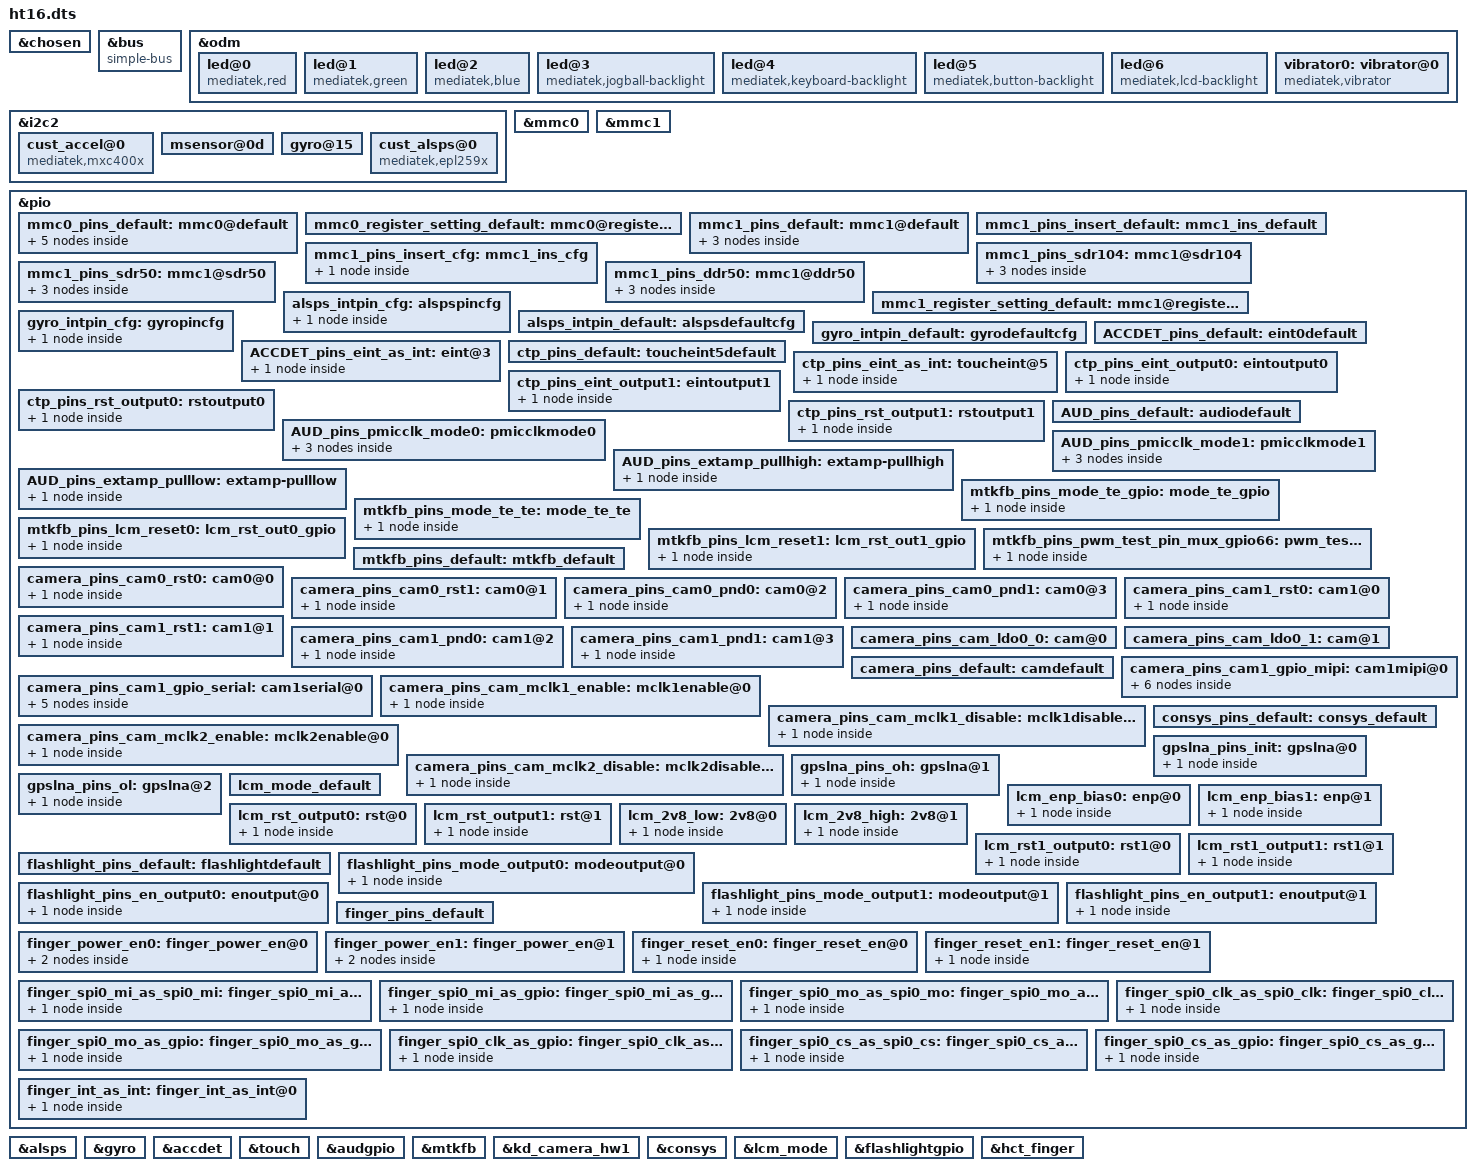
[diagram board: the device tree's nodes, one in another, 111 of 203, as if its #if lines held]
#include <generated/autoconf.h>
/dts-v1/;

#ifdef CONFIG_MTK_DTBO_FEATURE
/plugin/;
#include <dt-bindings/interrupt-controller/arm-gic.h>
#include <dt-bindings/interrupt-controller/irq.h>
#include "mt6580-pinfunc.h"
#include <dt-bindings/mmc/mt6580-msdc.h>
#else
#include "mt6580.dts"
#endif

/* chosen */
&chosen {
	bootargs = "console=tty0 console=ttyMT0,921600n1 root=/dev/ram initrd=0x84000000,0x400000 loglevel=8";
	/* fpga may has no lk, we need to specify display info here */
	/* fb buffer is reserved using this dts by memory node above */
	atag,videolfb-fb_base = <0x9E800000>;
	atag,videolfb-islcmfound = <1>;
	atag,videolfb-fps= <6000>;
	atag,videolfb-vramSize= <0x01800000>;
	atag,videolfb-lcmname= "nt35590_AUO";
};

&bus {
	compatible = "simple-bus";
	#address-cells = <1>;
	#size-cells = <1>;
	ranges = <0 0 0 0xffffffff>;
};

&odm {
	led@0 {
		compatible = "mediatek,red";
		led_mode = <0>;
		data = <1>;
		pwm_config = <0 0 0 0 0>;
	};
	led@1 {
		compatible = "mediatek,green";
		led_mode = <0>;
		data = <1>;
		pwm_config = <0 0 0 0 0>;
	};
	led@2 {
		compatible = "mediatek,blue";
		led_mode = <0>;
		data = <1>;
		pwm_config = <0 0 0 0 0>;
	};
	led@3 {
		compatible = "mediatek,jogball-backlight";
		led_mode = <0>;
		data = <1>;
		pwm_config = <0 0 0 0 0>;
	};
	led@4 {
		compatible = "mediatek,keyboard-backlight";
		led_mode = <0>;
		data = <1>;
		pwm_config = <0 0 0 0 0>;
	};
	led@5 {
		compatible = "mediatek,button-backlight";
		led_mode = <0>;
		data = <1>;
		pwm_config = <0 0 0 0 0>;
	};
	led@6 {
		compatible = "mediatek,lcd-backlight";
		led_mode = <5>;
		data = <1>;
		pwm_config = <0 0 0 0 0>;
	};
	vibrator0:vibrator@0 {
		compatible = "mediatek,vibrator";
		vib_timer = <25>;
		vib_limit = <9>;
		vib_vol= <6>;
	};
};

&i2c2 {
/* start sensor */
    cust_accel@0 {
		compatible				= "mediatek,mxc400x";
		i2c_num				    =  <2>;
		i2c_addr				= <0x15 0 0 0>;
		direction				= <3>;
		power_id				= <0xffff>;
		power_vol				= <0>;
		firlen					= <0>;
		is_batch_supported			= <0>;
    };

	msensor@0d {
		i2c_num = <2>;
		i2c_addr = <0x0D 0 0 0>;
		direction = <4>;
		power_id = <0xffff>;
		power_vol = <0>;
		is_batch_supported = <0>;
	};



	gyro@15 {
		i2c_num = <2>;
		i2c_addr = <0x15 0 0 0>;
		direction = <3>;
		power_id = <0xffff>;
		power_vol = <0>;
		firlen = <0>;
		is_batch_supported = <0>;
	};
    cust_alsps@0 {
        compatible            = "mediatek,epl259x";
        i2c_num	              = <2>;
        i2c_addr              = <0x49>;
        polling_mode_ps       = <0>;
        polling_mode_als      = <1>;
        power_id              = <0xffff>;
        power_vol             = <0>;
		als_level             = <0 400 900 1500 2325 3421 5067 6621 7062 8430 13274 27116 37694 57694 65535>;
		als_value             = <0 133 304 502 1004 2005 3058 4005 5008 6010 8000 12000 18000 20000 20000 20000>;
        ps_threshold_high	  = <200>;
        ps_threshold_low	  = <100>;
        is_batch_supported_ps = <0>;
        is_batch_supported_als= <0>;
    };
};

/* mmc start */
&mmc0 {
	clk_src = /bits/ 8 <MSDC0_CLKSRC_208MHZ>;
	bus-width = <8>;
	max-frequency = <208000000>;
	cap-mmc-highspeed;
	msdc-sys-suspend;
	mmc-hs200-1_8v;
	non-removable;
	pinctl = <&mmc0_pins_default>;
	register_setting = <&mmc0_register_setting_default>;
	host_function = /bits/ 8 <MSDC_EMMC>;
	bootable;
	status = "okay";
};

&mmc1 {
	clk_src = /bits/ 8 <MSDC1_CLKSRC_187MHZ>;
	bus-width = <4>;
	max-frequency = <208000000>;
	msdc-sys-suspend;
	cap-sd-highspeed;
	sd-uhs-sdr12;
	sd-uhs-sdr25;
	sd-uhs-sdr50;
	sd-uhs-sdr104;
	non-removable;
	pinctrl-names = "default","insert_cfg";
	pinctrl-0 = <&mmc1_pins_insert_default>;
	pinctrl-1 = <&mmc1_pins_insert_cfg>;
	pinctl = <&mmc1_pins_default>;
	pinctl_sdr104 = <&mmc1_pins_sdr104>;
	pinctl_sdr50 = <&mmc1_pins_sdr50>;
	pinctl_ddr50 = <&mmc1_pins_ddr50>;
	register_setting = <&mmc1_register_setting_default>;
	host_function = /bits/ 8 <MSDC_SD>;
	cd_level = /bits/ 8 <MSDC_CD_LOW>;
	cd-gpios = <&pio 3 0>;
	status = "okay";
};

&pio {
	mmc0_pins_default: mmc0@default {
		pins_cmd {
			drive-strength = /bits/ 8 <2>;
		};
		pins_dat {
			drive-strength = /bits/ 8 <2>;
		};
		pins_clk {
			drive-strength = /bits/ 8 <2>;
		};
		pins_rst {
			drive-strength = /bits/ 8 <2>;
		};
		pins_ds {
			drive-strength = /bits/ 8 <2>;
		};
	};

	mmc0_register_setting_default: mmc0@register_default {
		dat0rddly      = /bits/ 8 <0>;
		dat1rddly      = /bits/ 8 <0>;
		dat2rddly      = /bits/ 8 <0>;
		dat3rddly      = /bits/ 8 <0>;
		dat4rddly      = /bits/ 8 <0>;
		dat5rddly      = /bits/ 8 <0>;
		dat6rddly      = /bits/ 8 <0>;
		dat7rddly      = /bits/ 8 <0>;
		datwrddly      = /bits/ 8 <0>;
		cmdrrddly      = /bits/ 8 <0>;
		cmdrddly       = /bits/ 8 <0>;
		cmd_edge = /bits/ 8 <MSDC_SMPL_FALLING>;
		rdata_edge = /bits/ 8 <MSDC_SMPL_FALLING>;
		wdata_edge = /bits/ 8 <MSDC_SMPL_FALLING>;

		ett-hs200-cells = <12>;
		ett-hs200-default = <OFFSET_MSDC_PATCH_BIT0	MSDC_PB0_INT_DAT_LATCH_CK_SEL 0x0
			OFFSET_MSDC_PATCH_BIT0  MSDC_PB0_CKGEN_MSDC_DLY_SEL   0x0
			OFFSET_MSDC_PATCH_BIT1  MSDC_PB1_CMD_RSP_TA_CNTR      0x1
			OFFSET_MSDC_IOCON       MSDC_IOCON_RSPL               0x1
			OFFSET_MSDC_PAD_TUNE0   MSDC_PAD_TUNE0_CMDRDLY        0x0
			OFFSET_MSDC_PAD_TUNE0   MSDC_PAD_TUNE0_CMDRRDLY       0x0
			OFFSET_MSDC_PATCH_BIT1  MSDC_PB1_WRDAT_CRCS_TA_CNTR   0x1
			OFFSET_MSDC_PAD_TUNE0   MSDC_PAD_TUNE0_DATWRDLY       0x0
			OFFSET_MSDC_IOCON       MSDC_IOCON_W_D_SMPL           0x1
			OFFSET_MSDC_DAT_RDDLY0  MSDC_DAT_RDDLY0_D0            0x0
			OFFSET_MSDC_PAD_TUNE0   MSDC_PAD_TUNE0_DATRRDLY       0x0
			OFFSET_MSDC_PATCH_BIT0  MSDC_PB0_RD_DAT_SEL           0x1>;
	};

	mmc1_pins_default: mmc1@default {
		pins_cmd {
			drive-strength = /bits/ 8 <3>;
		};
		pins_dat {
			drive-strength = /bits/ 8 <3>;
		};
		pins_clk {
			drive-strength = /bits/ 8 <3>;
		};
	};

    mmc1_pins_insert_default: mmc1_ins_default {
	};
	mmc1_pins_insert_cfg: mmc1_ins_cfg {
		pins_insert {
			pins = <PINMUX_GPIO10__FUNC_EINT10>;
			input-schmitt-enable =<1>;
			slew-rate = <0>;
			bias-pull-up =<00>;
		};
	};
	
	mmc1_pins_sdr104: mmc1@sdr104 {
		pins_cmd {
			drive-strength = /bits/ 8 <2>;
		};
		pins_dat {
			drive-strength = /bits/ 8 <2>;
		};
		pins_clk {
			drive-strength = /bits/ 8 <3>;
		};
	};

	mmc1_pins_sdr50: mmc1@sdr50 {
		pins_cmd {
			drive-strength = /bits/ 8 <2>;
		};
		pins_dat {
			drive-strength = /bits/ 8 <2>;
		};
		pins_clk {
			drive-strength = /bits/ 8 <3>;
		};
	};

	mmc1_pins_ddr50: mmc1@ddr50 {
		pins_cmd {
			drive-strength = /bits/ 8 <2>;
		};
		pins_dat {
			drive-strength = /bits/ 8 <2>;
		};
		pins_clk {
			drive-strength = /bits/ 8 <3>;
		};
	};

	mmc1_register_setting_default: mmc1@register_default {
		dat0rddly      = /bits/ 8 <0>;
		dat1rddly      = /bits/ 8 <0>;
		dat2rddly      = /bits/ 8 <0>;
		dat3rddly      = /bits/ 8 <0>;
		datwrddly      = /bits/ 8 <0>;
		cmdrrddly      = /bits/ 8 <0>;
		cmdrddly       = /bits/ 8 <0>;
		cmd_edge = /bits/ 8 <MSDC_SMPL_FALLING>;
		rdata_edge = /bits/ 8 <MSDC_SMPL_FALLING>;
		wdata_edge = /bits/ 8 <MSDC_SMPL_FALLING>;
	};
};
/* mmc end */

&pio {
	alsps_intpin_cfg: alspspincfg {
	    pins_cmd_dat {
			pins = <PINMUX_GPIO6__FUNC_EINT6>;
			slew-rate = <0>;
			bias-pull-up = <00>;
		};
	};
	alsps_intpin_default: alspsdefaultcfg {
	};
	gyro_intpin_cfg: gyropincfg {
	    pins_cmd_dat {
			pins = <PINMUX_GPIO1__FUNC_GPIO1>;
			slew-rate = <0>;
			bias-pull-down = <00>;
		};
	};
	gyro_intpin_default: gyrodefaultcfg {
	};
};
&alsps {
	pinctrl-names = "pin_default", "pin_cfg";
	pinctrl-0 = <&alsps_intpin_default>;
	pinctrl-1 = <&alsps_intpin_cfg>;
	status = "okay";
};
&gyro {
	pinctrl-names = "pin_default", "pin_cfg";
	pinctrl-0 = <&gyro_intpin_default>;
	pinctrl-1 = <&gyro_intpin_cfg>;
	status = "okay";
};

&accdet {
	accdet-mic-vol = <7>;
	headset-mode-setting = <0x500 0x200 1 0x1F0 0x800 0x800 0x20>;
	accdet-plugout-debounce = <20>;
	/*1:ACC mode, 2:low cost without in bias, 6:low cost with in bias*/
	accdet-mic-mode = <1>;
	/*0--MD_MAX--UP_MAX--DW_MAX*/
	headset-three-key-threshold = <0 90 240 500>;
	/*0--MD_MAX--VOICE_MAX--UP_MAX--DW_MAX*/
	headset-four-key-threshold = <0 60 126 201 450>;
	/* ACCDET GPIO standardization ACC mode use */
	pinctrl-names = "default", "state_eint_as_int";
	pinctrl-0 = <&ACCDET_pins_default>;
	pinctrl-1 = <&ACCDET_pins_eint_as_int>;
	status = "okay";
};
&pio {
	ACCDET_pins_default: eint0default {
	};
	ACCDET_pins_eint_as_int: eint@3 {
		pins_cmd_dat {
			pins = <PINMUX_GPIO19__FUNC_EINT3>;
			slew-rate = <0>;
			bias-disable;
		};
	};
};
/*ACCDET END*/
/* TOUCH GPIO standardization */
&touch {
	tpd-resolution = <720 1280>;
	use-tpd-button = <1>;
	tpd-key-num = <4>;
	tpd-key-local= <139 158 172 0>;
	tpd-key-dim-local = <430 1350 60 50  90 1350 60 50 270 1350 60 50 630 1350 60 50>;
	tpd-max-touch-num = <5>;
	tpd-filter-enable = <1>;
	tpd-filter-pixel-density = <93>;
	tpd-filter-custom-prameters = <0 0 0 0 0 0 0 0 0 0 0 0>;
	tpd-filter-custom-speed = <0 0 0>;
	pinctrl-names = "default", "state_eint_as_int", "state_eint_output0", "state_eint_output1",
		"state_rst_output0", "state_rst_output1";
	pinctrl-0 = <&ctp_pins_default>;
	pinctrl-1 = <&ctp_pins_eint_as_int>;
	pinctrl-2 = <&ctp_pins_eint_output0>;
	pinctrl-3 = <&ctp_pins_eint_output1>;
	pinctrl-4 = <&ctp_pins_rst_output0>;
	pinctrl-5 = <&ctp_pins_rst_output1>;
	status = "okay";
};
&pio {
	ctp_pins_default: toucheint5default {
    };
	ctp_pins_eint_as_int: toucheint@5 {
		pins_cmd_dat {
			pins = <PINMUX_GPIO5__FUNC_EINT5>;
			slew-rate = <0>;
			bias-disable;
		};
	};
	ctp_pins_eint_output0: eintoutput0 {
		pins_cmd_dat {
			pins = <PINMUX_GPIO5__FUNC_GPIO5>;
			slew-rate = <1>;
			output-low;
		};
	};
	ctp_pins_eint_output1: eintoutput1 {
		pins_cmd_dat {
			pins = <PINMUX_GPIO5__FUNC_GPIO5>;
			slew-rate = <1>;
			output-high;
		};
	};
	ctp_pins_rst_output0: rstoutput0 {
		pins_cmd_dat {
			pins = <PINMUX_GPIO18__FUNC_GPIO18>;
			slew-rate = <1>;
			output-low;
		};
	};
	ctp_pins_rst_output1: rstoutput1 {
		pins_cmd_dat {
			pins = <PINMUX_GPIO18__FUNC_GPIO18>;
			slew-rate = <1>;
			output-high;
		};
	};
};
/* TOUCH end */

/* AUDIO GPIO standardization */
&audgpio {
	pinctrl-names = "default", "audpmicclk-mode0", "audpmicclk-mode1", "extamp-pullhigh", "extamp-pulllow";
	pinctrl-0 = <&AUD_pins_default>;
	pinctrl-1 = <&AUD_pins_pmicclk_mode0>;
	pinctrl-2 = <&AUD_pins_pmicclk_mode1>;
	pinctrl-3 = <&AUD_pins_extamp_pullhigh>;
	pinctrl-4 = <&AUD_pins_extamp_pulllow>;
	status = "okay";
};
&pio {
	AUD_pins_default: audiodefault {
	};
	AUD_pins_pmicclk_mode0: pmicclkmode0 {
		pins_cmd0_dat {
			pins = <PINMUX_GPIO26__FUNC_GPIO26>;
		};
		pins_cmd1_dat {
			pins = <PINMUX_GPIO28__FUNC_GPIO28>;
		};
		pins_cmd2_dat {
			pins = <PINMUX_GPIO27__FUNC_GPIO27>;
		};
	};
	AUD_pins_pmicclk_mode1: pmicclkmode1 {
		pins_cmd0_dat {
			pins = <PINMUX_GPIO26__FUNC_AUD_CLK_MOSI>;
		};
		pins_cmd1_dat {
			pins = <PINMUX_GPIO28__FUNC_AUD_DAT_MISO>;
		};
		pins_cmd2_dat {
			pins = <PINMUX_GPIO27__FUNC_AUD_DAT_MOSI>;
		};
	};
    AUD_pins_extamp_pullhigh: extamp-pullhigh{
        pins_cmd_dat{
			pins = <PINMUX_GPIO20__FUNC_GPIO20>;
			slew-rate = <1>;
			output-high;
        };
	};
	AUD_pins_extamp_pulllow: extamp-pulllow{
        pins_cmd_dat{
			pins = <PINMUX_GPIO20__FUNC_GPIO20>;
			slew-rate = <1>;
			output-low;
        };
	};
};
/* AUDIO end */

/* DISPSYS GPIO standardization */
&pio {

	mtkfb_pins_mode_te_gpio: mode_te_gpio {
		pins_cmd_dat {
			pins = <PINMUX_GPIO68__FUNC_GPIO68>;
		};
	};

	mtkfb_pins_mode_te_te: mode_te_te {
		pins_cmd_dat {
			pins = <PINMUX_GPIO68__FUNC_DSI_TE>;
		};
	};

	mtkfb_pins_lcm_reset0: lcm_rst_out0_gpio {
		pins_cmd_dat {
			pins = <PINMUX_GPIO70__FUNC_LCM_RST>;
			slew-rate = <1>;
			output-low;
		};
	};

	mtkfb_pins_lcm_reset1: lcm_rst_out1_gpio {
		pins_cmd_dat {
			pins = <PINMUX_GPIO70__FUNC_LCM_RST>;
			slew-rate = <1>;
			output-high;
		};
	};

	mtkfb_pins_pwm_test_pin_mux_gpio66: pwm_test_pin_mux_gpio66 {
		pins_cmd_dat {
			pins = <PINMUX_GPIO66__FUNC_DISP_PWM>;
			slew-rate = <1>;
		};
	};

	mtkfb_pins_default: mtkfb_default {
	};
};

&mtkfb {
	pinctrl-names = "default", "mode_te_gpio", "mode_te_te",
			"lcm_rst_out0_gpio", "lcm_rst_out1_gpio",
			"pwm_test_pin_mux_gpio66";
	pinctrl-0 = <&mtkfb_pins_default>;
	pinctrl-1 = <&mtkfb_pins_mode_te_gpio>;
	pinctrl-2 = <&mtkfb_pins_mode_te_te>;
	pinctrl-3 = <&mtkfb_pins_lcm_reset0>;
	pinctrl-4 = <&mtkfb_pins_lcm_reset1>;
	pinctrl-5 = <&mtkfb_pins_pwm_test_pin_mux_gpio66>;
	status = "okay";
};
/* DISPSYS GPIO standardization end */
/* CAMERA GPIO standardization */
&pio {
	camera_pins_cam0_rst0: cam0@0 {
	    pins_cmd_dat {
			pins = <PINMUX_GPIO73__FUNC_GPIO73>;/*GPIO_CAMERA_CMRST_PIN*/
			slew-rate = <1>; /*direction 0:in, 1:out*/
			output-low;/*direction out used only. output_low or high*/
		};
	};
	camera_pins_cam0_rst1: cam0@1 {
	    pins_cmd_dat {
			pins = <PINMUX_GPIO73__FUNC_GPIO73>;/*GPIO_CAMERA_CMRST_PIN*/
			slew-rate = <1>;
			output-high;
		};
	};
	camera_pins_cam0_pnd0: cam0@2 {
	    pins_cmd_dat {
			pins = <PINMUX_GPIO71__FUNC_GPIO71>;/*GPIO_CAMERA_CMPDN_PIN*/
			slew-rate = <1>;
			output-low;
		};
	};
	camera_pins_cam0_pnd1: cam0@3 {
	    pins_cmd_dat {
			pins = <PINMUX_GPIO71__FUNC_GPIO71>;/*GPIO_CAMERA_CMPDN_PIN*/
			slew-rate = <1>;
			output-high;
		};
	};
	camera_pins_cam1_rst0: cam1@0 {
	    pins_cmd_dat {
			pins = <PINMUX_GPIO76__FUNC_GPIO76>;/*GPIO_CAMERA_CMRST1_PIN*/
			slew-rate = <1>; /*direction 0:in, 1:out*/
			output-low;/*direction out used only. output_low or high*/
		};
	};
	camera_pins_cam1_rst1: cam1@1 {
	    pins_cmd_dat {
			pins = <PINMUX_GPIO76__FUNC_GPIO76>;/*GPIO_CAMERA_CMRST1_PIN*/
			slew-rate = <1>;
			output-high;
		};
	};
	camera_pins_cam1_pnd0: cam1@2 {
	    pins_cmd_dat {
			pins = <PINMUX_GPIO74__FUNC_GPIO74>;/*GPIO_CAMERA_CMPDN1_PIN*/
			slew-rate = <1>;
			output-low;
		};
	};
	camera_pins_cam1_pnd1: cam1@3 {
	    pins_cmd_dat {
			pins = <PINMUX_GPIO74__FUNC_GPIO74>;/*GPIO_CAMERA_CMPDN1_PIN*/
			slew-rate = <1>;
			output-high;
		};
	};
	camera_pins_cam_ldo0_0: cam@0 {
	};
	camera_pins_cam_ldo0_1: cam@1 {
	};
	camera_pins_default: camdefault {
	};
	camera_pins_cam1_gpio_serial: cam1serial@0{
	    pins_cmd_dat {
			pins = <PINMUX_GPIO35__FUNC_CMCSK>;
		};
	    pins_cmd_dat1 {
			pins = <PINMUX_GPIO36__FUNC_CMCSD0>;
		};
	    pins_cmd_dat2 {
			pins = <PINMUX_GPIO37__FUNC_CMCSD1>;
		};
	    pins_cmd_dat3 {
			pins = <PINMUX_GPIO38__FUNC_CMCSD2>;
		};
	    pins_cmd_dat4 {
			pins = <PINMUX_GPIO39__FUNC_CMCSD3>;
		};
	};
	camera_pins_cam1_gpio_mipi: cam1mipi@0{
	    pins_cmd_dat {
			pins = <PINMUX_GPIO35__FUNC_PAD_RDP0_A>;
		};
	    pins_cmd_dat1 {
			pins = <PINMUX_GPIO36__FUNC_PAD_RDN0_A>;
		};
	    pins_cmd_dat2 {
			pins = <PINMUX_GPIO37__FUNC_PAD_RDP1_A>;
		};
	    pins_cmd_dat3 {
			pins = <PINMUX_GPIO38__FUNC_PAD_RDN1_A>;
		};
	    pins_cmd_dat4 {
			pins = <PINMUX_GPIO39__FUNC_PAD_RCP_A>;
		};
	    pins_cmd_dat5 {
			pins = <PINMUX_GPIO40__FUNC_PAD_RCN_A>;
		};
	};
	camera_pins_cam_mclk1_enable: mclk1enable@0{
		pins_cmd_dat {
			pins = <PINMUX_GPIO72__FUNC_CAM_CLK0>;
		};
	};
	camera_pins_cam_mclk1_disable: mclk1disable@0{
	   pins_cmd_dat {
			pins = <PINMUX_GPIO72__FUNC_GPIO72>;
		};
	};
	camera_pins_cam_mclk2_enable: mclk2enable@0{
		pins_cmd_dat {
			pins = <PINMUX_GPIO75__FUNC_CAM_CLK1>;
		};
	};
	camera_pins_cam_mclk2_disable: mclk2disable@0{
		pins_cmd_dat {
			pins = <PINMUX_GPIO75__FUNC_GPIO75>;
		};
	};


};
&kd_camera_hw1 {
	pinctrl-names = "default", "cam0_rst0", "cam0_rst1", "cam0_pnd0", "cam0_pnd1",
				   "cam1_rst0", "cam1_rst1", "cam1_pnd0", "cam1_pnd1",
				   "cam_ldo0_0", "cam_ldo0_1", "cam1_gpio_serial", "cam1_gpio_mipi",
				   "cam_mclk1_enable","cam_mclk1_disable",
				   "cam_mclk2_enable","cam_mclk2_disable";
	pinctrl-0 = <&camera_pins_default>;
	pinctrl-1 = <&camera_pins_cam0_rst0>;
	pinctrl-2 = <&camera_pins_cam0_rst1>;
	pinctrl-3 = <&camera_pins_cam0_pnd0>;
	pinctrl-4 = <&camera_pins_cam0_pnd1>;
	pinctrl-5 = <&camera_pins_cam1_rst0>;
	pinctrl-6 = <&camera_pins_cam1_rst1>;
	pinctrl-7 = <&camera_pins_cam1_pnd0>;
	pinctrl-8 = <&camera_pins_cam1_pnd1>;
	pinctrl-9 = <&camera_pins_cam_ldo0_0>;
	pinctrl-10 = <&camera_pins_cam_ldo0_1>;
	pinctrl-11 = <&camera_pins_cam1_gpio_serial>;
	pinctrl-12 = <&camera_pins_cam1_gpio_mipi>;
	pinctrl-13 = <&camera_pins_cam_mclk1_enable>;
	pinctrl-14 = <&camera_pins_cam_mclk1_disable>;
	pinctrl-15 = <&camera_pins_cam_mclk2_enable>;
	pinctrl-16 = <&camera_pins_cam_mclk2_disable>;

	status = "okay";

};
/* CAMERA GPIO end */

/* CONSYS GPIO standardization */
&pio {
	consys_pins_default: consys_default {

	};

	gpslna_pins_init: gpslna@0 {

		pins_cmd_dat {
			pins = <PINMUX_GPIO65__FUNC_GPIO65>;
			slew-rate = <0>;
			bias-disable;
			output-low;
		};
	};

	gpslna_pins_oh: gpslna@1 {

		pins_cmd_dat {
			pins = <PINMUX_GPIO65__FUNC_GPIO65>;
			slew-rate = <1>;
			output-high;
		};
	};

	gpslna_pins_ol: gpslna@2 {

		pins_cmd_dat {
			pins = <PINMUX_GPIO65__FUNC_GPIO65>;
			slew-rate = <1>;
			output-low;
		};
	};

};

&consys {
	pinctrl-names = "default", "gps_lna_state_init", "gps_lna_state_oh", "gps_lna_state_ol";
	pinctrl-0 = <&consys_pins_default>;
	pinctrl-1 = <&gpslna_pins_init>;
	pinctrl-2 = <&gpslna_pins_oh>;
	pinctrl-3 = <&gpslna_pins_ol>;
	status = "okay";

};
/* CONSYS end */

/* LCM GPIO Kernal Standardization start */
&pio {
	lcm_mode_default: lcm_mode_default {
		};

    lcm_enp_bias0: enp@0 {
        pins_cmd_dat {
            pins = <PINMUX_GPIO15__FUNC_GPIO15>;
            slew-rate = <1>;
            output-low;
        };
    };
    lcm_enp_bias1: enp@1 {
        pins_cmd_dat {
            pins = <PINMUX_GPIO15__FUNC_GPIO15>;
            slew-rate = <1>;
            output-high;
        };
    };

    lcm_rst_output0: rst@0 {
        pins_cmd_dat {
            pins = <PINMUX_GPIO70__FUNC_GPIO70>;
            slew-rate = <1>;
            output-low;
        };
    };
    lcm_rst_output1: rst@1 {
        pins_cmd_dat {
            pins = <PINMUX_GPIO70__FUNC_GPIO70>;
            slew-rate = <1>;
            output-high;
        };
    };

    lcm_2v8_low: 2v8@0 {
        pins_cmd_dat {
            pins = <PINMUX_GPIO14__FUNC_GPIO14>;
            slew-rate = <1>;
            output-low;
        };
    };
    lcm_2v8_high: 2v8@1 {
        pins_cmd_dat {
            pins = <PINMUX_GPIO14__FUNC_GPIO14>;
            slew-rate = <1>;
            output-high;
        };
    };

    lcm_rst1_output0: rst1@0 {
        pins_cmd_dat {
            pins = <PINMUX_GPIO21__FUNC_GPIO21>;
            slew-rate = <1>;
            output-low;
        };
    };
    lcm_rst1_output1: rst1@1 {
        pins_cmd_dat {
            pins = <PINMUX_GPIO21__FUNC_GPIO21>;
            slew-rate = <1>;
            output-high;
        };
    };
};

&lcm_mode {
	pinctrl-names = "default", "lcm_enp_bias_l", "lcm_enp_bias_h", "lcm_rst_l", "lcm_rst_h", 
                    "lcm_2v8_l", "lcm_2v8_h", "lcm_rst1_l", "lcm_rst1_h";
	pinctrl-0 = <&lcm_mode_default>;
	pinctrl-1 = <&lcm_enp_bias0>;
	pinctrl-2 = <&lcm_enp_bias1>;
	pinctrl-3 = <&lcm_rst_output0>;
	pinctrl-4 = <&lcm_rst_output1>;
	pinctrl-5 = <&lcm_2v8_low>;
	pinctrl-6 = <&lcm_2v8_high>;
	pinctrl-7 = <&lcm_rst1_output0>;
	pinctrl-8 = <&lcm_rst1_output1>;
	status = "okay";
};
/* LCM GPIO Kernal Standardization end */

/* FLASHLIGHT GPIO standardization */
&pio {
	flashlight_pins_default: flashlightdefault {
	};
    flashlight_pins_mode_output0: modeoutput@0 {
		pins_cmd_dat {
			pins = <PINMUX_GPIO34__FUNC_GPIO34>;
			slew-rate = <1>;
			output-low;
		};
	};
	flashlight_pins_mode_output1: modeoutput@1 {
		pins_cmd_dat {
			pins = <PINMUX_GPIO34__FUNC_GPIO34>;
			slew-rate = <1>;
			output-high;
		};
	};
	flashlight_pins_en_output0: enoutput@0 {
		pins_cmd_dat {
			pins = <PINMUX_GPIO8__FUNC_GPIO8>;
			slew-rate = <1>;
			output-low;
		};
	};
	flashlight_pins_en_output1: enoutput@1 {
		pins_cmd_dat {
			pins = <PINMUX_GPIO8__FUNC_GPIO8>;
			slew-rate = <1>;
			output-high;
		};
	};
};
&flashlightgpio {
	pinctrl-names = "default", "state_mode_output0", "state_mode_output1",
	"state_en_output0", "state_en_output1";
	pinctrl-0 = <&flashlight_pins_default>;
	pinctrl-1 = <&flashlight_pins_mode_output0>;
	pinctrl-2 = <&flashlight_pins_mode_output1>;
	pinctrl-3 = <&flashlight_pins_en_output0>;
	pinctrl-4 = <&flashlight_pins_en_output1>;
	status = "okay";
};
/* FLASHLIGHT end */

#define __HCT_FINGERPRINT_EINT_EN_PIN_NUM__   9
#define __HCT_FINGERPRINT_EINT_PIN__    PINMUX_GPIO9__FUNC_EINT9

#define __HCT_FINGERPRINT_RESET_PIN__    PINMUX_GPIO17__FUNC_GPIO17

&hct_finger{
	pinctrl-names = "default", "finger_power_en0","finger_power_en1","finger_reset_en0","finger_reset_en1","finger_spi0_mi_as_spi0_mi","finger_spi0_mi_as_gpio",
                          "finger_spi0_mo_as_spi0_mo","finger_spi0_mo_as_gpio","finger_spi0_clk_as_spi0_clk","finger_spi0_clk_as_gpio","finger_spi0_cs_as_spi0_cs",
                          "finger_spi0_cs_as_gpio","finger_int_as_int";
	pinctrl-0 = <&finger_pins_default>;
	pinctrl-1 = <&finger_power_en0>;
	pinctrl-2 = <&finger_power_en1>;
	pinctrl-3 = <&finger_reset_en0>;
	pinctrl-4 = <&finger_reset_en1>;
	pinctrl-5 = <&finger_spi0_mi_as_spi0_mi>;
	pinctrl-6 = <&finger_spi0_mi_as_gpio>;
	pinctrl-7 = <&finger_spi0_mo_as_spi0_mo>;
	pinctrl-8 = <&finger_spi0_mo_as_gpio>;
	pinctrl-9 = <&finger_spi0_clk_as_spi0_clk>;
	pinctrl-10= <&finger_spi0_clk_as_gpio>;
	pinctrl-11= <&finger_spi0_cs_as_spi0_cs>;
	pinctrl-12= <&finger_spi0_cs_as_gpio>;
	pinctrl-13= <&finger_int_as_int>;
};

&hct_finger {
	interrupt-parent = <&eintc>;
	interrupts = <__HCT_FINGERPRINT_EINT_EN_PIN_NUM__ IRQ_TYPE_EDGE_FALLING>;
	debounce = <__HCT_FINGERPRINT_EINT_EN_PIN_NUM__ 0>;
	status = "okay";
};

/* flashlight GPIO standardization */
&pio {
/*******************finger pin start ****************/

	finger_pins_default:finger_pins_default{
	};
	finger_power_en0:finger_power_en@0{
		    pins_cmd0_dat {
			pins = <PINMUX_GPIO11__FUNC_GPIO11>;
			slew-rate = <1>;
			output-low;
		};
		    pins_cmd1_dat {
			pins = <PINMUX_GPIO12__FUNC_GPIO12>;
			slew-rate = <1>;
			output-low;
		};
	};
	finger_power_en1:finger_power_en@1{
		    pins_cmd0_dat {
			pins = <PINMUX_GPIO11__FUNC_GPIO11>;
			slew-rate = <1>;
			output-high;
		};
		    pins_cmd1_dat {
			pins = <PINMUX_GPIO12__FUNC_GPIO12>;
			slew-rate = <1>;
			output-high;
		};
	};
	finger_reset_en0:finger_reset_en@0{
		    pins_cmd_dat {
			pins = <__HCT_FINGERPRINT_RESET_PIN__>;
			slew-rate = <1>;
			output-low;
		};
	};
	finger_reset_en1:finger_reset_en@1{
		    pins_cmd_dat {
			pins = <__HCT_FINGERPRINT_RESET_PIN__>;
			slew-rate = <1>;
			output-high;
		};
	};
	finger_spi0_mi_as_spi0_mi:finger_spi0_mi_as_spi0_mi@0{
		    pins_cmd_dat {
			pins = <PINMUX_GPIO3__FUNC_SPI1_MISO>;
			slew-rate = <0>;
			
			output-low;
			
		};
	};
	finger_spi0_mi_as_gpio:finger_spi0_mi_as_gpio@0{
		    pins_cmd_dat {
			pins = <PINMUX_GPIO3__FUNC_GPIO3>;
			slew-rate = <0>;
			output-low;
			input-schmitt-enable = <0>;
		};
	};
	finger_spi0_mo_as_spi0_mo:finger_spi0_mo_as_spi0_mo@0{
		    pins_cmd_dat {
			pins = <PINMUX_GPIO2__FUNC_SPI1_MOSI>;
			slew-rate = <1>;
			
			output-low;
			
		};
	};
	finger_spi0_mo_as_gpio:finger_spi0_mo_as_gpio@0{
		    pins_cmd_dat {
			pins = <PINMUX_GPIO2__FUNC_GPIO2>;
			slew-rate = <1>;
			output-low;
			input-schmitt-enable = <0>;
		};
	};
	finger_spi0_clk_as_spi0_clk:finger_spi0_clk_as_spi0_clk@0{
		    pins_cmd_dat {
			pins = <PINMUX_GPIO1__FUNC_SPI1_SCK>;
			slew-rate = <1>;
			
			output-low;
			
		};
	};
	finger_spi0_clk_as_gpio:finger_spi0_clk_as_gpio@0{
		    pins_cmd_dat {
			pins = <PINMUX_GPIO1__FUNC_GPIO1>;
			slew-rate = <1>;
			output-low;
			input-schmitt-enable = <0>;
		};
	};
	finger_spi0_cs_as_spi0_cs:finger_spi0_cs_as_spi0_cs@0{
		    pins_cmd_dat {
			pins = <PINMUX_GPIO0__FUNC_SPI1_CS>;
			slew-rate = <1>;
			
			output-low;
			
		};
	};
	finger_spi0_cs_as_gpio:finger_spi0_cs_as_gpio@0{
		    pins_cmd_dat {
			pins = <PINMUX_GPIO0__FUNC_GPIO0>;
			slew-rate = <1>;
			output-low;
			input-schmitt-enable = <0>;
		};
	};
	finger_int_as_int: finger_int_as_int@0{
			pins_cmd_dat {
				pins = <__HCT_FINGERPRINT_EINT_PIN__>;
				slew-rate = <0>;
				bias-pull-up = <00>;
			};
	};
};
/*******************finger pin end ****************/

#include <x5/cust.dtsi>
/*End of this file, DO NOT ADD ANYTHING HERE*/
